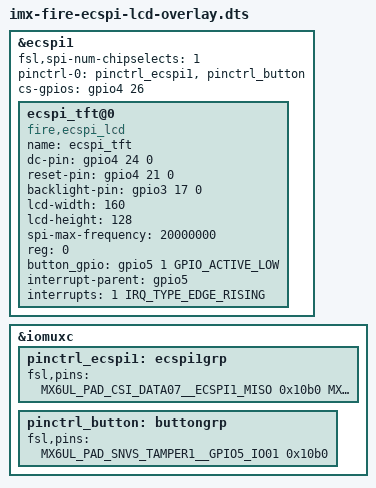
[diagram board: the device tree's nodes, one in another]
/*
 * Copyright (C) 2019 - All Rights Reserved by
 * filename : imx-fire-e_paper-overlay.dts
 * brief : Device Tree overlay for ecspi_e_paper device
 * author : DonGe
 * date :   2022-08-14
 * version : A001
 */
/dts-v1/;
/plugin/;

#include "../imx6ul-pinfunc.h"
#include "dt-bindings/interrupt-controller/irq.h"
#include "dt-bindings/gpio/gpio.h"

/ {
    fragment@0 {
        target = <&ecspi1>;
        __overlay__ {
            fsl,spi-num-chipselects = <1>;
			pinctrl-names = "default";
			pinctrl-0 = <&pinctrl_ecspi1>, <&pinctrl_button>;
			status = "okay";
			cs-gpios = <&gpio4 26 0>;
			#address-cells = <1>;
			#size-cells = <0>;
            ecspi_tft@0 {
				name = "ecspi_tft";
				compatible = "fire,ecspi_lcd";
				dc-pin = <&gpio4 24 0>;
                reset-pin = <&gpio4 21 0>;
                backlight-pin = <&gpio3 17 0>;
				lcd-width = <160>;
				lcd-height = <128>;
                spi-max-frequency = <20000000>;
                reg = <0>;
				status = "okay";

				button_gpio = <&gpio5 1 GPIO_ACTIVE_LOW>;
				interrupt-parent = <&gpio5>;
				interrupts = <1 IRQ_TYPE_EDGE_RISING>;

            };
        };
    };

    fragment@1 {
        target = <&iomuxc>;
        __overlay__ {
            pinctrl_ecspi1: ecspi1grp {
                fsl,pins = <
                    MX6UL_PAD_CSI_DATA07__ECSPI1_MISO  0x10b0
                    MX6UL_PAD_CSI_DATA06__ECSPI1_MOSI  0x10b0
                    MX6UL_PAD_CSI_DATA04__ECSPI1_SCLK  0x10b0
                    MX6UL_PAD_CSI_DATA03__GPIO4_IO24   0x10b0
                >;
            };
        };
    };
	fragment@2 {
		target = <&iomuxc>;
		__overlay__{
			pinctrl_button: buttongrp {
				fsl,pins =<
					MX6UL_PAD_SNVS_TAMPER1__GPIO5_IO01  0x10b0
				>;
			};
		};
	};
};
